AUTOSAR XML (schema 00051)
package /Components
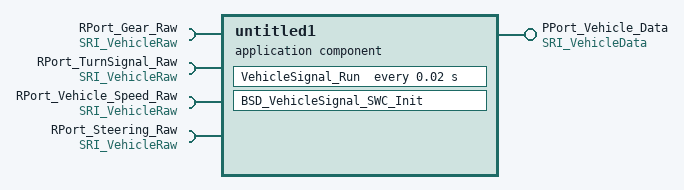
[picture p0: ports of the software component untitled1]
  application sw component type untitled1
    4 x require port, all with required-interface=SRI_VehicleRaw:
      RPort_Gear_Raw: nonqueued-receiver-com-spec{data-element=Raw_Gear_Position, init-value=0}
      RPort_TurnSignal_Raw: nonqueued-receiver-com-spec{data-element=Raw_Turn_Signal, init-value=0}
      RPort_Vehicle_Speed_Raw: nonqueued-receiver-com-spec{data-element=Raw_Vehicle_Speed, init-value=0}
      RPort_Steering_Raw: nonqueued-receiver-com-spec{data-element=Raw_Steering_Angle, init-value=0}
    provide port PPort_Vehicle_Data: provided-interface=SRI_VehicleData
      provided-com-specs:
        data-element=Vehicle_Speed, init-value=0
        data-element=Steering_Angle, init-value=0
        data-element=Turn_Signal, init-value=0
        data-element=Gear_Position, init-value=0
    behavior untitled1_IB: handle-termination-and-restart=NO-SUPPORT
      timing event TE_VehicleSignal_20ms: start-on-event=VehicleSignal_Run, period=0.02
      runnable VehicleSignal_Run
        data-read-access:
          4 x access:
            IN_RPort_Gear_Raw_Raw_Gear_Position: accessed-variable=RPort_Gear_Raw.Raw_Gear_Position
            IN_RPort_Steering_Raw_Raw_Steering_Angle: accessed-variable=RPort_Steering_Raw.Raw_Steering_Angle
            IN_RPort_TurnSignal_Raw_Raw_Turn_Signal: accessed-variable=RPort_TurnSignal_Raw.Raw_Turn_Signal
            IN_RPort_Vehicle_Speed_Raw_Raw_Vehicle_Speed: accessed-variable=RPort_Vehicle_Speed_Raw.Raw_Vehicle_Speed
        data-write-access:
          4 x access:
            OUT_PPort_Vehicle_Data_Vehicle_Speed: accessed-variable=PPort_Vehicle_Data.Vehicle_Speed
            OUT_PPort_Vehicle_Data_Steering_Angle: accessed-variable=PPort_Vehicle_Data.Steering_Angle
            OUT_PPort_Vehicle_Data_Turn_Signal: accessed-variable=PPort_Vehicle_Data.Turn_Signal
            OUT_PPort_Vehicle_Data_Gear_Position: accessed-variable=PPort_Vehicle_Data.Gear_Position
      runnable BSD_VehicleSignal_SWC_Init
